VERSION ""

NS_ :

BS_:

BU_: speed_controller daybreak_motor_controller daybreak_bms

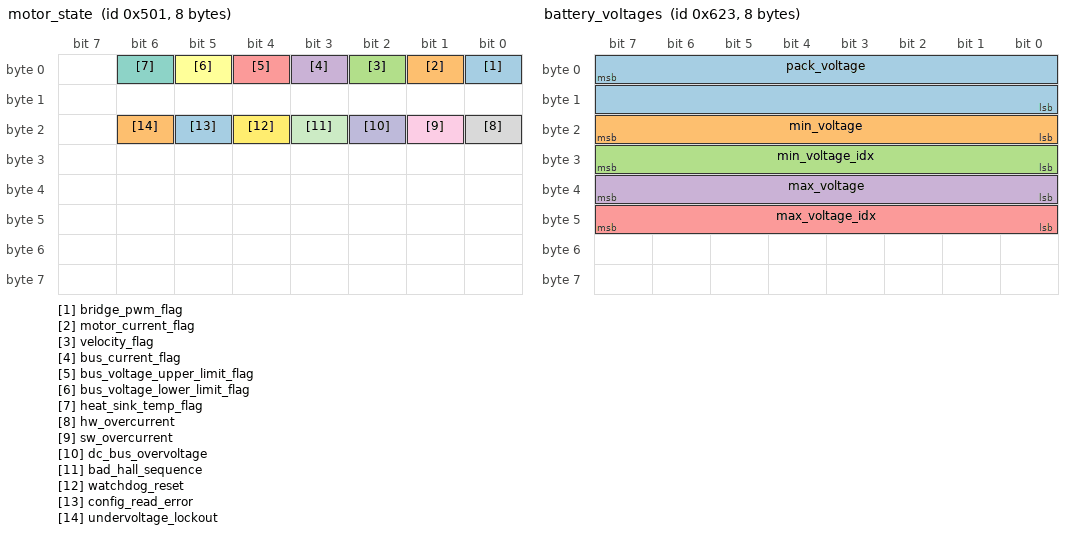
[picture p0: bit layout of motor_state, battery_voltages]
BO_ 1281 motor_state: 8 daybreak_motor_controller
 SG_ bridge_pwm_flag : 0|1@1+ (1,0) [0|0] "" Vector__XXX
 SG_ motor_current_flag : 1|1@1+ (1,0) [0|0] "" Vector__XXX
 SG_ velocity_flag : 2|1@1+ (1,0) [0|0] "" Vector__XXX
 SG_ bus_current_flag : 3|1@1+ (1,0) [0|0] "" Vector__XXX
 SG_ bus_voltage_upper_limit_flag : 4|1@1+ (1,0) [0|0] "" Vector__XXX
 SG_ bus_voltage_lower_limit_flag : 5|1@1+ (1,0) [0|0] "" Vector__XXX
 SG_ heat_sink_temp_flag : 6|1@1+ (1,0) [0|0] "" Vector__XXX
 SG_ hw_overcurrent : 16|1@1+ (1,0) [0|0] "" Vector__XXX
 SG_ sw_overcurrent : 17|1@1+ (1,0) [0|0] "" Vector__XXX
 SG_ dc_bus_overvoltage : 18|1@1+ (1,0) [0|0] "" Vector__XXX
 SG_ bad_hall_sequence : 19|1@1+ (1,0) [0|0] "" Vector__XXX
 SG_ watchdog_reset : 20|1@1+ (1,0) [0|0] "" Vector__XXX
 SG_ config_read_error : 21|1@1+ (1,0) [0|0] "" Vector__XXX
 SG_ undervoltage_lockout : 22|1@1+ (1,0) [0|0] "" Vector__XXX

BO_ 1282 motor_bus: 8 daybreak_motor_controller
 SG_ bus_voltage : 0|32@1- (1,0) [0|0] "V" Vector__XXX
 SG_ bus_current : 32|32@1- (1,0) [0|0] "A" Vector__XXX

BO_ 1283 motor_velocities: 8 daybreak_motor_controller
 SG_ motor_velocity : 0|32@1- (1,0) [0|0] "m/s" Vector__XXX
 SG_ vehicle_velocity : 32|32@1- (1,0) [0|0] "rpm" Vector__XXX

BO_ 1284 motor_phase: 8 daybreak_motor_controller
 SG_ phase_b_current : 0|32@1- (1,0) [0|0] "A" Vector__XXX
 SG_ phase_a_current : 32|32@1- (1,0) [0|0] "A" Vector__XXX

BO_ 1291 motor_temperatures: 8 daybreak_motor_controller
 SG_ motor_temperature : 0|32@1- (1,0) [0|0] "degC" Vector__XXX
 SG_ heatsink_temperature : 32|32@1- (1,0) [0|0] "degC" Vector__XXX

BO_ 1025 drive_command: 8 speed_controller
 SG_ desired_velocity : 0|32@1- (1,0) [0|100] "m/s" Vector__XXX
 SG_ current_setpoint : 32|32@1- (1,0) [0|1] "%" Vector__XXX

BO_ 1570 battery_metadata: 8 daybreak_bms
 SG_ fault_state : 0|1@1+ (1,0) [0|0] "" Vector__XXX
 SG_ contactor_k1 : 1|1@1+ (1,0) [0|0] "" Vector__XXX
 SG_ contactor_k2 : 2|1@1+ (1,0) [0|0] "" Vector__XXX
 SG_ contactor_k3 : 3|1@1+ (1,0) [0|0] "" Vector__XXX
 SG_ relay_fault : 4|1@1+ (1,0) [0|0] "" Vector__XXX
 SG_ startup_time : 15|16@0+ (1,0) [0|0] "" Vector__XXX
 SG_ source_power : 24|1@1+ (1,0) [0|0] "" Vector__XXX
 SG_ load_power : 25|1@1+ (1,0) [0|0] "" Vector__XXX
 SG_ interlock_tripped : 26|1@1+ (1,0) [0|0] "" Vector__XXX
 SG_ hard_wire_contactor_request : 27|1@1+ (1,0) [0|0] "" Vector__XXX
 SG_ can_contactor_request : 28|1@1+ (1,0) [0|0] "" Vector__XXX
 SG_ hlim_set : 29|1@1+ (1,0) [0|0] "" Vector__XXX
 SG_ llim_set : 30|1@1+ (1,0) [0|0] "" Vector__XXX
 SG_ fan_on : 31|1@1+ (1,0) [0|0] "" Vector__XXX
 SG_ fault_code : 32|8@1+ (1,0) [0|0] "" Vector__XXX
 SG_ driving_off : 40|1@1+ (1,0) [0|0] "" Vector__XXX
 SG_ iterlock_tripped_lf : 41|1@1+ (1,0) [0|0] "" Vector__XXX
 SG_ communication_fault : 42|1@1+ (1,0) [0|0] "" Vector__XXX
 SG_ charge_overcurrent : 43|1@1+ (1,0) [0|0] "" Vector__XXX
 SG_ discharge_overcurrent : 44|1@1+ (1,0) [0|0] "" Vector__XXX
 SG_ over_temperature : 45|1@1+ (1,0) [0|0] "" Vector__XXX
 SG_ under_voltage : 46|1@1+ (1,0) [0|0] "" Vector__XXX
 SG_ over_voltage : 47|1@1+ (1,0) [0|0] "" Vector__XXX
 SG_ low_voltage_warn : 48|1@1+ (1,0) [0|0] "" Vector__XXX
 SG_ high_voltage_warn : 49|1@1+ (1,0) [0|0] "" Vector__XXX
 SG_ charge_overcurrent_warn : 50|1@1+ (1,0) [0|0] "" Vector__XXX
 SG_ discharge_overcurrent_warn : 51|1@1+ (1,0) [0|0] "" Vector__XXX
 SG_ cold_temperature_warn : 52|1@1+ (1,0) [0|0] "" Vector__XXX
 SG_ hot_temperature_warn : 53|1@1+ (1,0) [0|0] "" Vector__XXX
 SG_ low_soh_warn : 54|1@1+ (1,0) [0|0] "" Vector__XXX
 SG_ isolation_fault_warn : 55|1@1+ (1,0) [0|0] "" Vector__XXX

BO_ 1571 battery_voltages: 8 daybreak_bms
 SG_ pack_voltage : 7|16@0+ (1,0) [0|65536] "V" Vector__XXX
 SG_ min_voltage : 16|8@1+ (0.1,0) [0|25.5] "V" Vector__XXX
 SG_ min_voltage_idx : 24|8@1+ (1,0) [0|255] "" Vector__XXX
 SG_ max_voltage : 32|8@1+ (0.1,0) [0|25.5] "V" Vector__XXX
 SG_ max_voltage_idx : 40|8@1+ (1,0) [0|255] "" Vector__XXX

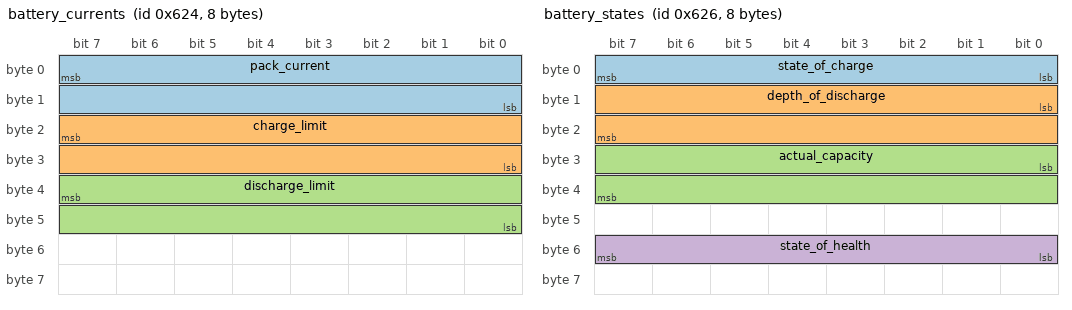
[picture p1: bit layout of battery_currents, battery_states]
BO_ 1572 battery_currents: 8 daybreak_bms
 SG_ pack_current : 7|16@0- (1,0) [-32768|32767] "A" Vector__XXX
 SG_ charge_limit : 23|16@0+ (1,0) [0|65536] "A" Vector__XXX
 SG_ discharge_limit : 39|16@0+ (1,0) [0|65536] "A" Vector__XXX

BO_ 1573 battery_energies: 8 daybreak_bms
 SG_ battery_energy_in : 0|32@1+ (1,0) [0|4294967296] "kWh" Vector__XXX
 SG_ battery_energy_out : 32|32@1+ (1,0) [0|4294967296] "kWh" Vector__XXX

BO_ 1574 battery_states: 8 daybreak_bms
 SG_ state_of_charge : 0|8@1+ (1,0) [0|100] "%" Vector__XXX
 SG_ depth_of_discharge : 8|16@1+ (1,0) [0|65536] "Ah" Vector__XXX
 SG_ actual_capacity : 24|16@1+ (1,0) [0|65536] "Ah" Vector__XXX
 SG_ state_of_health : 48|8@1+ (1,0) [0|100] "%" Vector__XXX

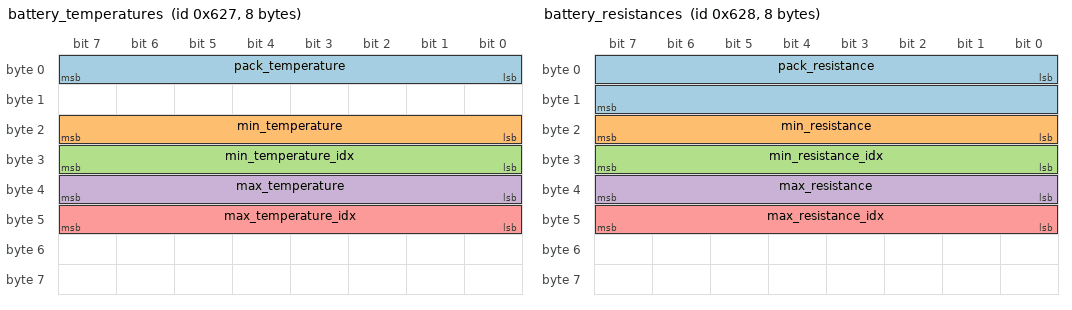
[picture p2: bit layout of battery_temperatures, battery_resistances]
BO_ 1575 battery_temperatures: 8 daybreak_bms
 SG_ pack_temperature : 0|8@1- (1,0) [-127|127] "degC" Vector__XXX
 SG_ min_temperature : 16|8@1- (1,0) [-127|127] "degC" Vector__XXX
 SG_ min_temperature_idx : 24|8@1+ (1,0) [0|255] "" Vector__XXX
 SG_ max_temperature : 32|8@1- (1,0) [-127|127] "degC" Vector__XXX
 SG_ max_temperature_idx : 40|8@1+ (1,0) [0|255] "" Vector__XXX

BO_ 1576 battery_resistances: 8 daybreak_bms
 SG_ pack_resistance : 0|16@1+ (0.1,0) [0|6553.5] "milliohm" Vector__XXX
 SG_ min_resistance : 16|8@1+ (0.1,0) [0|25.5] "milliohm" Vector__XXX
 SG_ min_resistance_idx : 24|8@1+ (1,0) [0|255] "" Vector__XXX
 SG_ max_resistance : 32|8@1+ (0.1,0) [0|25.5] "milliohm" Vector__XXX
 SG_ max_resistance_idx : 40|8@1+ (1,0) [0|255] "" Vector__XXX

CM_ SG_ 1571 pack_voltage "Total voltage of pack as the sum of all cell voltages";
CM_ SG_ 1571 min_voltage "Voltage of least charged cell";
CM_ SG_ 1571 min_voltage_idx "ID of the cell with the smallest voltage";
CM_ SG_ 1571 max_voltage "Voltage of most charged cell";
CM_ SG_ 1571 max_voltage_idx "ID of the cell with the greatest voltage";
CM_ SG_ 1572 pack_current "Positive out of pack, negative into pack, averaged over 1s";
CM_ SG_ 1572 charge_limit "Maximum current acceptable";
CM_ SG_ 1572 discharge_limit "Maximum current available";
CM_ SG_ 1573 battery_energy_in "Total energy in since manufacture";
CM_ SG_ 1573 battery_energy_out "Total energy out since manufacture";
CM_ SG_ 1575 min_temperature "Temperature of coldest sensor";
CM_ SG_ 1575 min_temperature_idx "ID of sensor with coldest temperature";
CM_ SG_ 1575 max_temperature "Temperature of hottest sensor";
CM_ SG_ 1575 max_temperature_idx "ID of sensor with hottest temperature";
BA_DEF_  "BusType" STRING ;
BA_DEF_DEF_  "BusType" "CAN";
SIG_VALTYPE_ 1282 bus_voltage : 1;
SIG_VALTYPE_ 1282 bus_current : 1;
SIG_VALTYPE_ 1283 motor_velocity : 1;
SIG_VALTYPE_ 1283 vehicle_velocity : 1;
SIG_VALTYPE_ 1284 phase_b_current : 1;
SIG_VALTYPE_ 1284 phase_a_current : 1;
SIG_VALTYPE_ 1291 motor_temperature : 1;
SIG_VALTYPE_ 1291 heatsink_temperature : 1;
SIG_VALTYPE_ 1025 desired_velocity : 1;
SIG_VALTYPE_ 1025 current_setpoint : 1;
